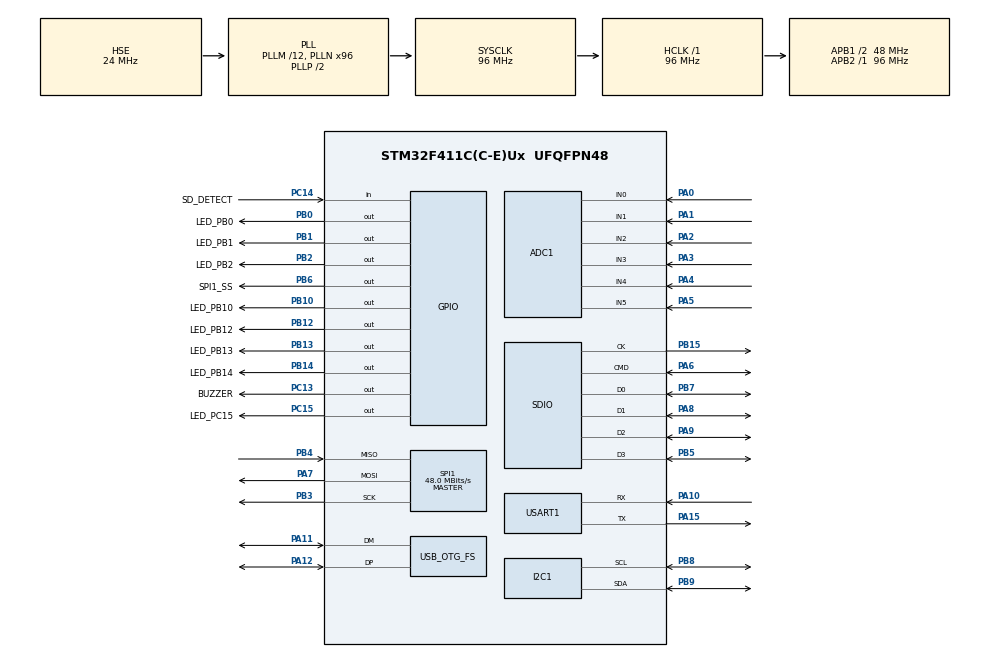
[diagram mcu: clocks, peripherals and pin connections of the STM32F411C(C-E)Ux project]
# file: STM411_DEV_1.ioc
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ADC1.Channel-0\#ChannelRegularConversion=ADC_CHANNEL_0
ADC1.NbrOfConversionFlag=1
ADC1.Rank-0\#ChannelRegularConversion=1
ADC1.SamplingTime-0\#ChannelRegularConversion=ADC_SAMPLETIME_3CYCLES
ADC1.master=1
FATFS.BSP.number=1
FATFS._FS_EXFAT=1
FATFS._MAX_SS=4096
FATFS._USE_CHMOD=1
FATFS._USE_EXPAND=1
FATFS._USE_FIND=1
FATFS._USE_FORWARD=1
FATFS._USE_LABEL=1
FATFS._USE_LFN=1
FATFS._USE_MKFS=1
FATFS0.BSP.STBoard=false
FATFS0.BSP.api=Unknown
FATFS0.BSP.instance=PC14-OSC32_IN
FATFS0.BSP.ip=GPIO
FATFS0.BSP.mode=Input
FATFS0.BSP.name=Detect_SDIO
FATFS0.BSP.solution=PC14-OSC32_IN
Mcu.Family=STM32F4
Mcu.Name=STM32F411C(C-E)Ux
Mcu.Package=UFQFPN48
NVIC.OTG_FS_IRQn=true\:0\:0\:false\:false\:true\:true\:true\:true
NVIC.PriorityGroup=NVIC_PRIORITYGROUP_4
NVIC.SDIO_IRQn=true\:0\:0\:false\:false\:true\:true\:true\:true
NVIC.TIM1_BRK_TIM9_IRQn=true\:0\:0\:false\:false\:true\:true\:true\:true
NVIC.TIM1_CC_IRQn=true\:0\:0\:false\:false\:true\:true\:true\:true
NVIC.TIM1_TRG_COM_TIM11_IRQn=true\:0\:0\:false\:false\:true\:true\:true\:true
NVIC.TIM1_UP_TIM10_IRQn=true\:0\:0\:false\:false\:true\:true\:true\:true
PA0-WKUP.Signal=ADCx_IN0
PA1.Signal=ADCx_IN1
PA10.Mode=Asynchronous
PA10.Signal=USART1_RX
PA11.Mode=Device_Only
PA11.Signal=USB_OTG_FS_DM
PA12.Mode=Device_Only
PA12.Signal=USB_OTG_FS_DP
PA13.Mode=Serial_Wire
PA13.Signal=SYS_JTMS-SWDIO
PA14.Mode=Serial_Wire
PA14.Signal=SYS_JTCK-SWCLK
PA15.Mode=Asynchronous
PA15.Signal=USART1_TX
PA2.Signal=ADCx_IN2
PA3.Signal=ADCx_IN3
PA4.Signal=ADCx_IN4
PA5.Signal=ADCx_IN5
PA6.GPIO_Speed_High_Default=GPIO_SPEED_FREQ_LOW
PA6.Mode=SD_4_bits_Wide_bus
PA6.Signal=SDIO_CMD
PA7.Mode=Full_Duplex_Master
PA7.Signal=SPI1_MOSI
PA8.GPIO_Speed_High_Default=GPIO_SPEED_FREQ_LOW
PA8.Mode=SD_4_bits_Wide_bus
PA8.Signal=SDIO_D1
PA9.GPIO_Speed_High_Default=GPIO_SPEED_FREQ_LOW
PA9.Mode=SD_4_bits_Wide_bus
PA9.Signal=SDIO_D2
PB0.GPIO_Label=LED_PB0
PB0.Signal=GPIO_Output
PB1.GPIO_Label=LED_PB1
PB1.Signal=GPIO_Output
PB10.GPIO_Label=LED_PB10
PB10.Signal=GPIO_Output
PB12.GPIO_Label=LED_PB12
PB12.Signal=GPIO_Output
PB13.GPIO_Label=LED_PB13
PB13.Signal=GPIO_Output
PB14.GPIO_Label=LED_PB14
PB14.Signal=GPIO_Output
PB15.GPIO_Speed_High_Default=GPIO_SPEED_FREQ_LOW
PB15.Mode=SD_4_bits_Wide_bus
PB15.Signal=SDIO_CK
PB2.GPIO_Label=LED_PB2
PB2.Signal=GPIO_Output
PB3.Mode=Full_Duplex_Master
PB3.Signal=SPI1_SCK
PB4.Mode=Full_Duplex_Master
PB4.Signal=SPI1_MISO
PB5.GPIO_Speed_High_Default=GPIO_SPEED_FREQ_LOW
PB5.Mode=SD_4_bits_Wide_bus
PB5.Signal=SDIO_D3
PB6.GPIO_Label=SPI1_SS
PB6.Signal=GPIO_Output
PB7.GPIO_Speed_High_Default=GPIO_SPEED_FREQ_LOW
PB7.Mode=SD_4_bits_Wide_bus
PB7.Signal=SDIO_D0
PB8.Mode=I2C
PB8.Signal=I2C1_SCL
PB9.Mode=I2C
PB9.Signal=I2C1_SDA
PC13-ANTI_TAMP.GPIO_Label=BUZZER
PC13-ANTI_TAMP.Signal=GPIO_Output
PC14-OSC32_IN.GPIO_Label=SD_DETECT
PC14-OSC32_IN.GPIO_PuPd=GPIO_NOPULL
PC14-OSC32_IN.Signal=GPIO_Input
PC15-OSC32_OUT.GPIO_Label=LED_PC15
PC15-OSC32_OUT.GPIO_PuPd=GPIO_NOPULL
PC15-OSC32_OUT.Signal=GPIO_Output
PH0\ -\ OSC_IN.Mode=HSE-External-Oscillator
PH0\ -\ OSC_IN.Signal=RCC_OSC_IN
PH1\ -\ OSC_OUT.Mode=HSE-External-Oscillator
PH1\ -\ OSC_OUT.Signal=RCC_OSC_OUT
ProjectManager.HeapSize=0x800
ProjectManager.StackSize=0x800
ProjectManager.TargetToolchain=STM32CubeIDE
RCC.48MHZClocksFreq_Value=48000000
RCC.AHBFreq_Value=96000000
RCC.APB1CLKDivider=RCC_HCLK_DIV2
RCC.APB1Freq_Value=48000000
RCC.APB1TimFreq_Value=96000000
RCC.APB2Freq_Value=96000000
RCC.APB2TimFreq_Value=96000000
RCC.CortexFreq_Value=96000000
RCC.HCLKFreq_Value=96000000
RCC.HSE_VALUE=24000000
RCC.HSI_VALUE=16000000
RCC.LSE_VALUE=32768
RCC.PLLM=12
RCC.PLLMUL=RCC_PLL_MUL9
RCC.PLLN=96
RCC.RCC_PLLsource_Clock_Source_FROM_HSE=RCC_HSE_PREDIV_DIV2
RCC.SYSCLKFreq_VALUE=96000000
RCC.SYSCLKSource=RCC_SYSCLKSOURCE_PLLCLK
RCC.SYSCLKSourceVirtual=RCC_SYSCLKSOURCE_PLLCLK
RCC.VCOOutputFreq_Value=192000000
SDIO.ClockDiv=7
SH.ADCx_IN0.0=ADC1_IN0,IN0
SH.ADCx_IN1.0=ADC1_IN1,IN1
SH.ADCx_IN2.0=ADC1_IN2,IN2
SH.ADCx_IN3.0=ADC1_IN3,IN3
SH.ADCx_IN4.0=ADC1_IN4,IN4
SH.ADCx_IN5.0=ADC1_IN5,IN5
SPI1.BaudRatePrescaler=SPI_BAUDRATEPRESCALER_2
SPI1.CalculateBaudRate=48.0 MBits/s
SPI1.Direction=SPI_DIRECTION_2LINES
SPI1.Mode=SPI_MODE_MASTER
SPI1.VirtualType=VM_MASTER
STMicroelectronics.X-CUBE-AI.10.2.0.HeapSize=0x800
STMicroelectronics.X-CUBE-AI.10.2.0.ReadyForCodeGeneration=false
STMicroelectronics.X-CUBE-AI.10.2.0.StackSize=0x800
STMicroelectronics.X-CUBE-AI.10.2.0.copyWeightToRam=false
STMicroelectronics.X-CUBE-AI.10.2.0.customLayerConfigEnabled=false
STMicroelectronics.X-CUBE-AI.10.2.0.noOnnxIoTranspose=false
STMicroelectronics.X-CUBE-AI.10.2.0.useInputAllocation=true
STMicroelectronics.X-CUBE-AI.10.2.0.useOutputAllocation=true
TIM1.Prescaler=950
USART1.VirtualMode=VM_ASYNC
USB_DEVICE.CLASS_NAME_FS=MSC
USB_DEVICE.MSC_MEDIA_PACKET=32768
USB_DEVICE.USBD_DEBUG_LEVEL=0
USB_DEVICE.VirtualMode=Msc
USB_DEVICE.VirtualModeFS=Msc_FS
USB_OTG_FS.VirtualMode=Device_Only
VP_FATFS_VS_SDIO.Mode=SDIO
VP_RTC_VS_RTC_Activate.Mode=RTC_Enabled
VP_TIM1_VS_ClockSourceINT.Mode=Internal
VP_USB_DEVICE_VS_USB_DEVICE_MSC_FS.Mode=MSC_FS
board=custom

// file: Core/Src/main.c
/* USER CODE BEGIN Header */
/**
  ******************************************************************************
  * @file           : main.c
  * @brief          : Main program body
  ******************************************************************************
  * @attention
  *
  * Copyright (c) 2025 STMicroelectronics.
  * All rights reserved.
  *
  * This software is licensed under terms that can be found in the LICENSE file
  * in the root directory of this software component.
  * If no LICENSE file comes with this software, it is provided AS-IS.
  *
  ******************************************************************************
  */
/* USER CODE END Header */
#include "main.h"
#include "fatfs.h"
#include "usb_device.h"

ADC_HandleTypeDef hadc1;

I2C_HandleTypeDef hi2c1;

RTC_HandleTypeDef hrtc;

SD_HandleTypeDef hsd;

SPI_HandleTypeDef hspi1;

TIM_HandleTypeDef htim1;

UART_HandleTypeDef huart1;

void SystemClock_Config(void);
static void MX_GPIO_Init(void);
static void MX_ADC1_Init(void);
static void MX_I2C1_Init(void);
static void MX_RTC_Init(void);
static void MX_SPI1_Init(void);
static void MX_USART1_UART_Init(void);
static void MX_SDIO_SD_Init(void);
static void MX_TIM1_Init(void);

int main(void)
{

  /* USER CODE BEGIN 1 */
  FRESULT res;
  FATFS fs;
  /* USER CODE END 1 */

  /* MCU Configuration--------------------------------------------------------*/

  /* Reset of all peripherals, Initializes the Flash interface and the Systick. */
  HAL_Init();

  /* Configure the system clock */
  SystemClock_Config();

  /* Initialize all configured peripherals */
  MX_GPIO_Init();
  MX_ADC1_Init();
  MX_I2C1_Init();
  MX_RTC_Init();
  MX_SPI1_Init();
  MX_USART1_UART_Init();
  MX_USB_DEVICE_Init();
  MX_SDIO_SD_Init();
  MX_TIM1_Init();
  MX_FATFS_Init();
  /* USER CODE BEGIN 2 */
  res = f_mount(&fs, "0:", 1);
  if (res != FR_OK) {
  /* Mount failed - you might want to handle this */
  /* Optional: blink LED or send message via UART */
  } else {
  /* Mount successful */
  }
  /* USER CODE END 2 */

  /* Infinite loop */
  while (1)
  {

  }
}

void SystemClock_Config(void)
{
  RCC_OscInitTypeDef RCC_OscInitStruct = {0};
  RCC_ClkInitTypeDef RCC_ClkInitStruct = {0};

  /** Configure the main internal regulator output voltage
  */
  __HAL_RCC_PWR_CLK_ENABLE();
  __HAL_PWR_VOLTAGESCALING_CONFIG(PWR_REGULATOR_VOLTAGE_SCALE1);

  /** Initializes the RCC Oscillators according to the specified parameters
  * in the RCC_OscInitTypeDef structure.
  */
  RCC_OscInitStruct.OscillatorType = RCC_OSCILLATORTYPE_LSI|RCC_OSCILLATORTYPE_HSE;
  RCC_OscInitStruct.HSEState = RCC_HSE_ON;
  RCC_OscInitStruct.LSIState = RCC_LSI_ON;
  RCC_OscInitStruct.PLL.PLLState = RCC_PLL_ON;
  RCC_OscInitStruct.PLL.PLLSource = RCC_PLLSOURCE_HSE;
  RCC_OscInitStruct.PLL.PLLM = 12;
  RCC_OscInitStruct.PLL.PLLN = 96;
  RCC_OscInitStruct.PLL.PLLP = RCC_PLLP_DIV2;
  RCC_OscInitStruct.PLL.PLLQ = 4;
  if (HAL_RCC_OscConfig(&RCC_OscInitStruct) != HAL_OK)
  {
    Error_Handler();
  }

  /** Initializes the CPU, AHB and APB buses clocks
  */
  RCC_ClkInitStruct.ClockType = RCC_CLOCKTYPE_HCLK|RCC_CLOCKTYPE_SYSCLK
                              |RCC_CLOCKTYPE_PCLK1|RCC_CLOCKTYPE_PCLK2;
  RCC_ClkInitStruct.SYSCLKSource = RCC_SYSCLKSOURCE_PLLCLK;
  RCC_ClkInitStruct.AHBCLKDivider = RCC_SYSCLK_DIV1;
  RCC_ClkInitStruct.APB1CLKDivider = RCC_HCLK_DIV2;
  RCC_ClkInitStruct.APB2CLKDivider = RCC_HCLK_DIV1;

  if (HAL_RCC_ClockConfig(&RCC_ClkInitStruct, FLASH_LATENCY_3) != HAL_OK)
  {
    Error_Handler();
  }
}

static void MX_ADC1_Init(void)
{

  ADC_ChannelConfTypeDef sConfig = {0};

  /** Configure the global features of the ADC (Clock, Resolution, Data Alignment and number of conversion)
  */
  hadc1.Instance = ADC1;
  hadc1.Init.ClockPrescaler = ADC_CLOCK_SYNC_PCLK_DIV4;
  hadc1.Init.Resolution = ADC_RESOLUTION_12B;
  hadc1.Init.ScanConvMode = DISABLE;
  hadc1.Init.ContinuousConvMode = DISABLE;
  hadc1.Init.DiscontinuousConvMode = DISABLE;
  hadc1.Init.ExternalTrigConvEdge = ADC_EXTERNALTRIGCONVEDGE_NONE;
  hadc1.Init.ExternalTrigConv = ADC_SOFTWARE_START;
  hadc1.Init.DataAlign = ADC_DATAALIGN_RIGHT;
  hadc1.Init.NbrOfConversion = 1;
  hadc1.Init.DMAContinuousRequests = DISABLE;
  hadc1.Init.EOCSelection = ADC_EOC_SINGLE_CONV;
  if (HAL_ADC_Init(&hadc1) != HAL_OK)
  {
    Error_Handler();
  }

  /** Configure for the selected ADC regular channel its corresponding rank in the sequencer and its sample time.
  */
  sConfig.Channel = ADC_CHANNEL_0;
  sConfig.Rank = 1;
  sConfig.SamplingTime = ADC_SAMPLETIME_3CYCLES;
  if (HAL_ADC_ConfigChannel(&hadc1, &sConfig) != HAL_OK)
  {
    Error_Handler();
  }

}

static void MX_I2C1_Init(void)
{

  hi2c1.Instance = I2C1;
  hi2c1.Init.ClockSpeed = 100000;
  hi2c1.Init.DutyCycle = I2C_DUTYCYCLE_2;
  hi2c1.Init.OwnAddress1 = 0;
  hi2c1.Init.AddressingMode = I2C_ADDRESSINGMODE_7BIT;
  hi2c1.Init.DualAddressMode = I2C_DUALADDRESS_DISABLE;
  hi2c1.Init.OwnAddress2 = 0;
  hi2c1.Init.GeneralCallMode = I2C_GENERALCALL_DISABLE;
  hi2c1.Init.NoStretchMode = I2C_NOSTRETCH_DISABLE;
  if (HAL_I2C_Init(&hi2c1) != HAL_OK)
  {
    Error_Handler();
  }

}

static void MX_RTC_Init(void)
{

  /** Initialize RTC Only
  */
  hrtc.Instance = RTC;
  hrtc.Init.HourFormat = RTC_HOURFORMAT_24;
  hrtc.Init.AsynchPrediv = 127;
  hrtc.Init.SynchPrediv = 255;
  hrtc.Init.OutPut = RTC_OUTPUT_DISABLE;
  hrtc.Init.OutPutPolarity = RTC_OUTPUT_POLARITY_HIGH;
  hrtc.Init.OutPutType = RTC_OUTPUT_TYPE_OPENDRAIN;
  if (HAL_RTC_Init(&hrtc) != HAL_OK)
  {
    Error_Handler();
  }

}

static void MX_SDIO_SD_Init(void)
{

  hsd.Instance = SDIO;
  hsd.Init.ClockEdge = SDIO_CLOCK_EDGE_RISING;
  hsd.Init.ClockBypass = SDIO_CLOCK_BYPASS_DISABLE;
  hsd.Init.ClockPowerSave = SDIO_CLOCK_POWER_SAVE_DISABLE;
  hsd.Init.BusWide = SDIO_BUS_WIDE_1B;
  hsd.Init.HardwareFlowControl = SDIO_HARDWARE_FLOW_CONTROL_DISABLE;
  hsd.Init.ClockDiv = 7;
  /* USER CODE BEGIN SDIO_Init 2 */
  if (HAL_SD_Init(&hsd) != HAL_OK)
  {
    Error_Handler();
  }
  if (HAL_SD_ConfigWideBusOperation(&hsd, SDIO_BUS_WIDE_4B) != HAL_OK)
  {
    Error_Handler();
  }
  /* USER CODE END SDIO_Init 2 */

}

static void MX_SPI1_Init(void)
{

  /* SPI1 parameter configuration*/
  hspi1.Instance = SPI1;
  hspi1.Init.Mode = SPI_MODE_MASTER;
  hspi1.Init.Direction = SPI_DIRECTION_2LINES;
  hspi1.Init.DataSize = SPI_DATASIZE_8BIT;
  hspi1.Init.CLKPolarity = SPI_POLARITY_LOW;
  hspi1.Init.CLKPhase = SPI_PHASE_1EDGE;
  hspi1.Init.NSS = SPI_NSS_SOFT;
  hspi1.Init.BaudRatePrescaler = SPI_BAUDRATEPRESCALER_2;
  hspi1.Init.FirstBit = SPI_FIRSTBIT_MSB;
  hspi1.Init.TIMode = SPI_TIMODE_DISABLE;
  hspi1.Init.CRCCalculation = SPI_CRCCALCULATION_DISABLE;
  hspi1.Init.CRCPolynomial = 10;
  if (HAL_SPI_Init(&hspi1) != HAL_OK)
  {
    Error_Handler();
  }

}

static void MX_TIM1_Init(void)
{

  TIM_ClockConfigTypeDef sClockSourceConfig = {0};
  TIM_MasterConfigTypeDef sMasterConfig = {0};

  htim1.Instance = TIM1;
  htim1.Init.Prescaler = 950;
  htim1.Init.CounterMode = TIM_COUNTERMODE_UP;
  htim1.Init.Period = 65535;
  htim1.Init.ClockDivision = TIM_CLOCKDIVISION_DIV1;
  htim1.Init.RepetitionCounter = 0;
  htim1.Init.AutoReloadPreload = TIM_AUTORELOAD_PRELOAD_DISABLE;
  if (HAL_TIM_Base_Init(&htim1) != HAL_OK)
  {
    Error_Handler();
  }
  sClockSourceConfig.ClockSource = TIM_CLOCKSOURCE_INTERNAL;
  if (HAL_TIM_ConfigClockSource(&htim1, &sClockSourceConfig) != HAL_OK)
  {
    Error_Handler();
  }
  sMasterConfig.MasterOutputTrigger = TIM_TRGO_RESET;
  sMasterConfig.MasterSlaveMode = TIM_MASTERSLAVEMODE_DISABLE;
  if (HAL_TIMEx_MasterConfigSynchronization(&htim1, &sMasterConfig) != HAL_OK)
  {
    Error_Handler();
  }

}

static void MX_USART1_UART_Init(void)
{

  huart1.Instance = USART1;
  huart1.Init.BaudRate = 115200;
  huart1.Init.WordLength = UART_WORDLENGTH_8B;
  huart1.Init.StopBits = UART_STOPBITS_1;
  huart1.Init.Parity = UART_PARITY_NONE;
  huart1.Init.Mode = UART_MODE_TX_RX;
  huart1.Init.HwFlowCtl = UART_HWCONTROL_NONE;
  huart1.Init.OverSampling = UART_OVERSAMPLING_16;
  if (HAL_UART_Init(&huart1) != HAL_OK)
  {
    Error_Handler();
  }

}

static void MX_GPIO_Init(void)
{
  GPIO_InitTypeDef GPIO_InitStruct = {0};

  /* GPIO Ports Clock Enable */
  __HAL_RCC_GPIOC_CLK_ENABLE();
  __HAL_RCC_GPIOH_CLK_ENABLE();
  __HAL_RCC_GPIOA_CLK_ENABLE();
  __HAL_RCC_GPIOB_CLK_ENABLE();

  /*Configure GPIO pin Output Level */
  HAL_GPIO_WritePin(GPIOC, BUZZER_Pin|LED_PC15_Pin, GPIO_PIN_RESET);

  /*Configure GPIO pin Output Level */
  HAL_GPIO_WritePin(GPIOB, LED_PB0_Pin|LED_PB1_Pin|LED_PB2_Pin|LED_PB10_Pin
                          |LED_PB12_Pin|LED_PB13_Pin|LED_PB14_Pin|SPI1_SS_Pin, GPIO_PIN_RESET);

  /*Configure GPIO pins : BUZZER_Pin LED_PC15_Pin */
  GPIO_InitStruct.Pin = BUZZER_Pin|LED_PC15_Pin;
  GPIO_InitStruct.Mode = GPIO_MODE_OUTPUT_PP;
  GPIO_InitStruct.Pull = GPIO_NOPULL;
  GPIO_InitStruct.Speed = GPIO_SPEED_FREQ_LOW;
  HAL_GPIO_Init(GPIOC, &GPIO_InitStruct);

  /*Configure GPIO pin : SD_DETECT_Pin */
  GPIO_InitStruct.Pin = SD_DETECT_Pin;
  GPIO_InitStruct.Mode = GPIO_MODE_INPUT;
  GPIO_InitStruct.Pull = GPIO_NOPULL;
  HAL_GPIO_Init(SD_DETECT_GPIO_Port, &GPIO_InitStruct);

  /*Configure GPIO pins : LED_PB0_Pin LED_PB1_Pin LED_PB2_Pin LED_PB10_Pin
                           LED_PB12_Pin LED_PB13_Pin LED_PB14_Pin SPI1_SS_Pin */
  GPIO_InitStruct.Pin = LED_PB0_Pin|LED_PB1_Pin|LED_PB2_Pin|LED_PB10_Pin
                          |LED_PB12_Pin|LED_PB13_Pin|LED_PB14_Pin|SPI1_SS_Pin;
  GPIO_InitStruct.Mode = GPIO_MODE_OUTPUT_PP;
  GPIO_InitStruct.Pull = GPIO_NOPULL;
  GPIO_InitStruct.Speed = GPIO_SPEED_FREQ_LOW;
  HAL_GPIO_Init(GPIOB, &GPIO_InitStruct);

}

void Error_Handler(void)
{
  __disable_irq();
  while (1)
  {
  }
}
